AUTOSAR XML (schema 4.0)
package /B/If
  7 x sender receiver interface:
    MediaReq
      data payload
    NavRoute
      data route
    ComfortMode
      data mode
    DiagCmd
      data cmd
    Trajectory
      data curve
    DecelReq
      data decel
    BrakeForce
      data force
package /B/Swc
  application sw component type BluetoothStack
    provide port MediaOut: provided-interface=MediaReq
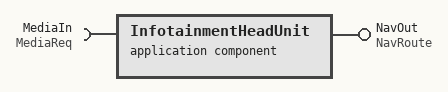
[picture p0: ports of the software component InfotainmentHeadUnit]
  application sw component type InfotainmentHeadUnit
    require port MediaIn: required-interface=MediaReq
    provide port NavOut: provided-interface=NavRoute
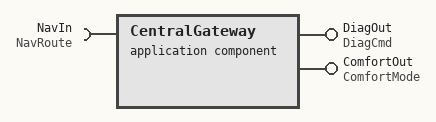
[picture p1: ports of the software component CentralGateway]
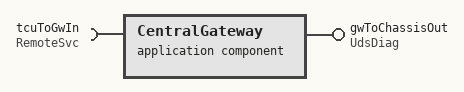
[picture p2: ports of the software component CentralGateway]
  application sw component type CentralGateway
    require port NavIn: required-interface=NavRoute
    provide port DiagOut: provided-interface=DiagCmd
    provide port ComfortOut: provided-interface=ComfortMode
  application sw component type DiagnosticRouter
    require port DiagIn: required-interface=DiagCmd
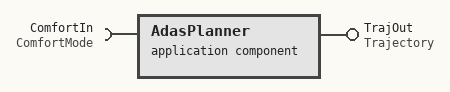
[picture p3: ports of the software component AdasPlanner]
  application sw component type AdasPlanner
    require port ComfortIn: required-interface=ComfortMode
    provide port TrajOut: provided-interface=Trajectory
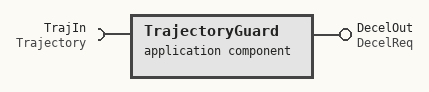
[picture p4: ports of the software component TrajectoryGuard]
  application sw component type TrajectoryGuard
    require port TrajIn: required-interface=Trajectory
    provide port DecelOut: provided-interface=DecelReq
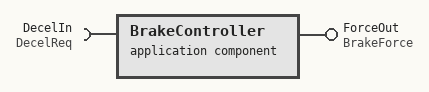
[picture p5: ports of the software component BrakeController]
  application sw component type BrakeController
    require port DecelIn: required-interface=DecelReq
    provide port ForceOut: provided-interface=BrakeForce
  sensor actuator sw component type BrakeActuator
    require port ForceIn: required-interface=BrakeForce
  composition sw component type ScenarioB
    8 x component:
      btStack: type=BluetoothStack
      ivi: type=InfotainmentHeadUnit
      gw: type=Swc/CentralGateway
      diagRouter: type=DiagnosticRouter
      adas: type=AdasPlanner
      trajGuard: type=TrajectoryGuard
      brakeCtl: type=BrakeController
      brakeAct: type=BrakeActuator
    connect btStack.MediaOut -> ivi.MediaIn
    connect ivi.NavOut -> gw.NavIn
    connect gw.DiagOut -> diagRouter.DiagIn
    connect adas.TrajOut -> trajGuard.TrajIn
    connect trajGuard.DecelOut -> brakeCtl.DecelIn
    connect brakeCtl.ForceOut -> brakeAct.ForceIn
package /B/Comm
  pdu NavIPdu
    signal NavISig: system signal NavSSig
  secured i pdu NavSecuredIPdu: auth-info-tx-length=32, freshness-value-id=1, freshness-value-length=8, payload=NavIPdu
  pdu ComfortIPdu
    signal ComfortISig: system signal ComfortSSig
  pdu DecelIPdu
    signal DecelISig: system signal DecelSSig
  secured i pdu DecelSecuredIPdu: auth-info-tx-length=32, freshness-value-id=2, freshness-value-length=8, payload=DecelIPdu
package /B/Topology
  4 x ecu instance:
    IviEcu
    GatewayEcu
    AdasEcu
    ChassisEcu
  system ScenarioB
    root-software-compositions:
      root sw composition prototype Root: software-composition=ScenarioB
    system mapping Map
      data-mappings:
        data-element=Root.NavOut.route, system-signal=NavSSig
        data-element=Root.ComfortOut.mode, system-signal=ComfortSSig
        data-element=Root.DecelOut.decel, system-signal=DecelSSig
      sw-mappings:
        4 x swc to ecu mapping:
          ToIvi: component=[btStack, ivi], ecu-instance=IviEcu
          ToGateway: component=[gw, diagRouter], ecu-instance=Topology/GatewayEcu
          ToAdas: component=[adas, trajGuard], ecu-instance=AdasEcu
          ToChassis: component=[brakeCtl, brakeAct], ecu-instance=Topology/ChassisEcu
package /S02CONN/If
  sender receiver interface RemoteSvc
    data val
  sender receiver interface UdsDiag
    data val
package /S02CONN/Swc
  application sw component type TelematicsUnit
    provide port tcuToGwOut: provided-interface=RemoteSvc
  application sw component type CentralGateway
    require port tcuToGwIn: required-interface=RemoteSvc
    provide port gwToChassisOut: provided-interface=UdsDiag
  application sw component type ChassisCtrl
    require port gwToChassisIn: required-interface=UdsDiag
  composition sw component type Root
    component tcu: type=TelematicsUnit
    component cgw: type=Swc/CentralGateway
    component chassis: type=ChassisCtrl
    connect tcu.tcuToGwOut -> cgw.tcuToGwIn
    connect cgw.gwToChassisOut -> chassis.gwToChassisIn
package /S02CONN/Comm
  pdu tcuToGwIPdu
    signal tcuToGwISig: system signal tcuToGwSSig
  secured i pdu tcuToGwSecuredIPdu: auth-info-tx-length=32, freshness-value-id=1, freshness-value-length=8, payload=tcuToGwIPdu
  pdu gwToChassisIPdu
    signal gwToChassisISig: system signal gwToChassisSSig
package /S02CONN/Topology
  ecu instance ChassisEcu
  ecu instance GatewayEcu
  ecu instance TcuEcu
  system Veh
    root-software-compositions:
      root sw composition prototype Root: software-composition=Root
    system mapping Map
      data-mappings:
        data-element=Root.tcuToGwOut.val, system-signal=tcuToGwSSig
        data-element=Root.gwToChassisOut.val, system-signal=gwToChassisSSig
      sw-mappings:
        swc to ecu mapping ToChassisEcu: component=chassis, ecu-instance=Topology/ChassisEcu
        swc to ecu mapping ToGatewayEcu: component=cgw, ecu-instance=Topology/GatewayEcu
        swc to ecu mapping ToTcuEcu: component=tcu, ecu-instance=TcuEcu
